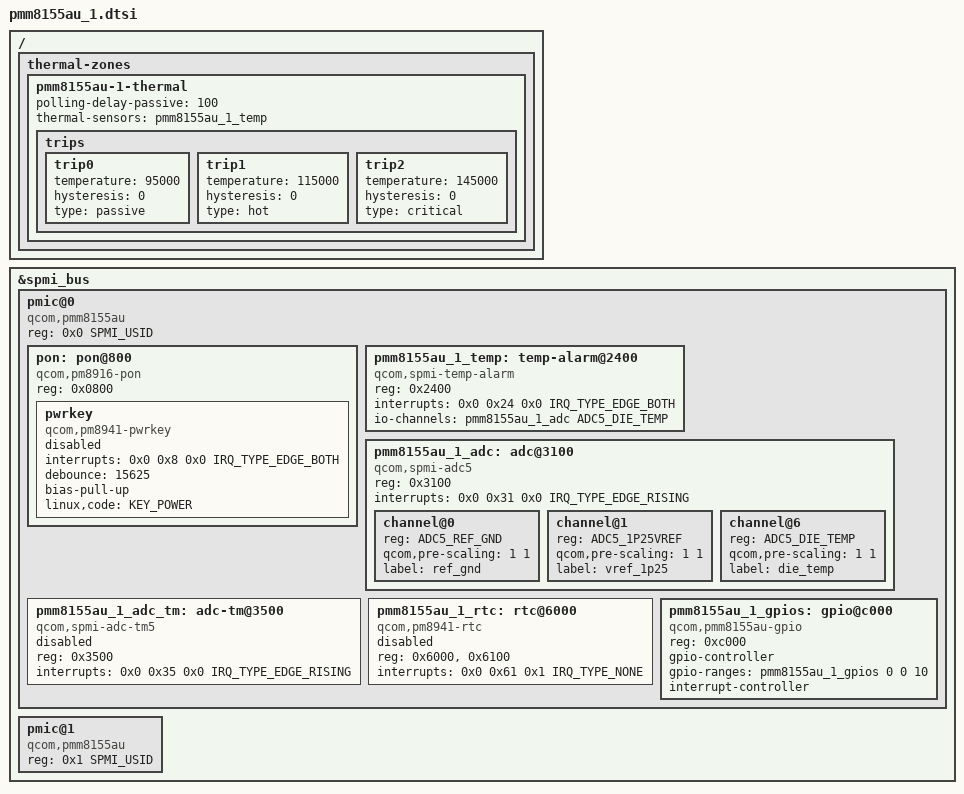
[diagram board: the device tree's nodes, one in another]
// SPDX-License-Identifier: BSD-3-Clause
/*
 * Copyright (c) 2021, Linaro Limited
 */

#include <dt-bindings/input/input.h>
#include <dt-bindings/interrupt-controller/irq.h>
#include <dt-bindings/spmi/spmi.h>
#include <dt-bindings/iio/qcom,spmi-vadc.h>

/ {
	thermal-zones {
		pmm8155au-1-thermal {
			polling-delay-passive = <100>;

			thermal-sensors = <&pmm8155au_1_temp>;

			trips {
				trip0 {
					temperature = <95000>;
					hysteresis = <0>;
					type = "passive";
				};

				trip1 {
					temperature = <115000>;
					hysteresis = <0>;
					type = "hot";
				};

				trip2 {
					temperature = <145000>;
					hysteresis = <0>;
					type = "critical";
				};
			};
		};
	};
};

&spmi_bus {
	pmic@0 {
		compatible = "qcom,pmm8155au", "qcom,spmi-pmic";
		reg = <0x0 SPMI_USID>;
		#address-cells = <1>;
		#size-cells = <0>;

		pon: pon@800 {
			compatible = "qcom,pm8916-pon";
			reg = <0x0800>;
			pwrkey {
				compatible = "qcom,pm8941-pwrkey";
				interrupts = <0x0 0x8 0x0 IRQ_TYPE_EDGE_BOTH>;
				debounce = <15625>;
				bias-pull-up;
				linux,code = <KEY_POWER>;

				status = "disabled";
			};
		};

		pmm8155au_1_temp: temp-alarm@2400 {
			compatible = "qcom,spmi-temp-alarm";
			reg = <0x2400>;
			interrupts = <0x0 0x24 0x0 IRQ_TYPE_EDGE_BOTH>;
			io-channels = <&pmm8155au_1_adc ADC5_DIE_TEMP>;
			io-channel-names = "thermal";
			#thermal-sensor-cells = <0>;
		};

		pmm8155au_1_adc: adc@3100 {
			compatible = "qcom,spmi-adc5";
			reg = <0x3100>;
			#address-cells = <1>;
			#size-cells = <0>;
			#io-channel-cells = <1>;
			interrupts = <0x0 0x31 0x0 IRQ_TYPE_EDGE_RISING>;

			channel@0 {
				reg = <ADC5_REF_GND>;
				qcom,pre-scaling = <1 1>;
				label = "ref_gnd";
			};

			channel@1 {
				reg = <ADC5_1P25VREF>;
				qcom,pre-scaling = <1 1>;
				label = "vref_1p25";
			};

			channel@6 {
				reg = <ADC5_DIE_TEMP>;
				qcom,pre-scaling = <1 1>;
				label = "die_temp";
			};
		};

		pmm8155au_1_adc_tm: adc-tm@3500 {
			compatible = "qcom,spmi-adc-tm5";
			reg = <0x3500>;
			interrupts = <0x0 0x35 0x0 IRQ_TYPE_EDGE_RISING>;
			#thermal-sensor-cells = <1>;
			#address-cells = <1>;
			#size-cells = <0>;
			status = "disabled";
		};

		pmm8155au_1_rtc: rtc@6000 {
			compatible = "qcom,pm8941-rtc";
			reg = <0x6000>, <0x6100>;
			reg-names = "rtc", "alarm";
			interrupts = <0x0 0x61 0x1 IRQ_TYPE_NONE>;

			status = "disabled";
		};

		pmm8155au_1_gpios: gpio@c000 {
			compatible = "qcom,pmm8155au-gpio", "qcom,spmi-gpio";
			reg = <0xc000>;
			gpio-controller;
			#gpio-cells = <2>;
			gpio-ranges = <&pmm8155au_1_gpios 0 0 10>;
			interrupt-controller;
			#interrupt-cells = <2>;
		};
	};

	pmic@1 {
		compatible = "qcom,pmm8155au", "qcom,spmi-pmic";
		reg = <0x1 SPMI_USID>;
		#address-cells = <1>;
		#size-cells = <0>;
	};
};
